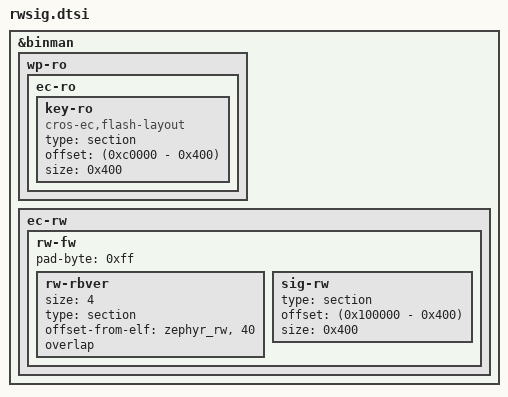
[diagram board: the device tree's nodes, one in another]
/* Copyright 2024 The ChromiumOS Authors.
 * Use of this source code is governed by a BSD-style license that can be
 * found in the LICENSE file.
 */

&binman {
	wp-ro {
		ec-ro {
			key-ro {
				compatible = "cros-ec,flash-layout";
				type = "section";
				offset = <(0xc0000 - 0x400)>;
				size = <0x400>;
			};
		};
	};

	ec-rw {
		rw-fw {
			// TODO confirm that node
			rw-rbver {
				size = <4>;
				type = "section";
				/* points to
				 * current_image_data.rollback_version
				 */
				offset-from-elf = <&zephyr_rw>,
					"current_image_data", <40>;
				overlap;
			};

			sig-rw {
				type = "section";
				/* Offset within rw-fw */
				offset = <(0x100000 - 0x400)>;
				size = <0x400>;
			};
			pad-byte = <0xff>;
		};
	};
};
